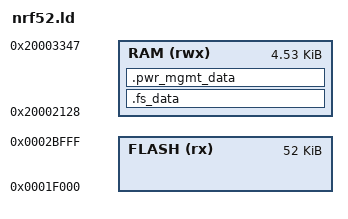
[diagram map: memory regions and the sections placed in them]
/* Linker script to configure memory regions. */

SEARCH_DIR(.)
GROUP(-lgcc -lc -lnosys)

MEMORY
{
  FLASH (rx) : ORIGIN = 0x1f000, LENGTH = 0xd000
  RAM (rwx) :  ORIGIN = 0x20002128, LENGTH = 0x1220
}

SECTIONS
{
  .fs_data :
  {
    PROVIDE(__start_fs_data = .);
    KEEP(*(.fs_data))
    PROVIDE(__stop_fs_data = .);
  } > RAM
  .pwr_mgmt_data :
  {
    PROVIDE(__start_pwr_mgmt_data = .);
    KEEP(*(.pwr_mgmt_data))
    PROVIDE(__stop_pwr_mgmt_data = .);
  } > RAM

    PROVIDE(__stack = 0x20010000);
} INSERT AFTER .data;


INCLUDE "nrf5x_common.ld"

